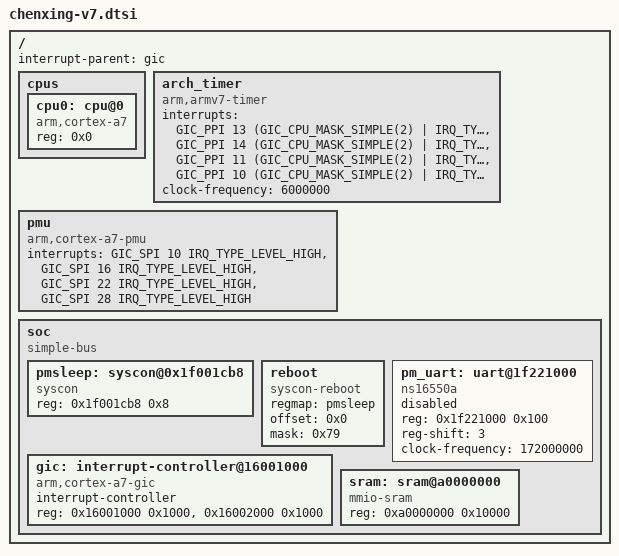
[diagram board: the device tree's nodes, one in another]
// SPDX-License-Identifier: GPL-2.0
/*
 * Copyright (c) 2019 thingy.jp.
 * Author: Daniel Palmer <daniel@thingy.jp>
 */

#include <dt-bindings/interrupt-controller/irq.h>
#include <dt-bindings/interrupt-controller/arm-gic.h>

/ {
	#address-cells = <1>;
	#size-cells = <1>;
	interrupt-parent = <&gic>;

	cpus {
		#address-cells = <1>;
		#size-cells = <0>;

		cpu0: cpu@0 {
			device_type = "cpu";
			compatible = "arm,cortex-a7";
			reg = <0x0>;
		};
	};

	arch_timer {
		compatible = "arm,armv7-timer";
		interrupts = <GIC_PPI 13 (GIC_CPU_MASK_SIMPLE(2)
				| IRQ_TYPE_LEVEL_LOW)>,
			     <GIC_PPI 14 (GIC_CPU_MASK_SIMPLE(2)
				| IRQ_TYPE_LEVEL_LOW)>,
			     <GIC_PPI 11 (GIC_CPU_MASK_SIMPLE(2)
				| IRQ_TYPE_LEVEL_LOW)>,
			     <GIC_PPI 10 (GIC_CPU_MASK_SIMPLE(2)
				| IRQ_TYPE_LEVEL_LOW)>;
		clock-frequency = <6000000>;
	};

	pmu {
		compatible = "arm,cortex-a7-pmu";
		interrupts = <GIC_SPI 10 IRQ_TYPE_LEVEL_HIGH>,
			     <GIC_SPI 16 IRQ_TYPE_LEVEL_HIGH>,
			     <GIC_SPI 22 IRQ_TYPE_LEVEL_HIGH>,
			     <GIC_SPI 28 IRQ_TYPE_LEVEL_HIGH>;
	};

	soc: soc {
		compatible = "simple-bus";
		#address-cells = <1>;
		#size-cells = <1>;
		ranges;

		pmsleep: syscon@0x1f001cb8 {
			/* msc313e notes */
			/* 0x1f001c00 - wake up source */
			/*
			 * 1f001c24 -- bit 11 disables pm uart rx
			 * -- bit 15 is set when going into deep sleep
			 *
			 * mysteryclk1 1f001cf4
			 * 0x1f001cc0 -- ??
			 * 0x1f001cc8  -- set to 9fe8 before deep sleep
			 * 0x1f001ccc  -- set to 9fe8 before deep sleep
			 * 0x1f001cdc  -- set to 0xa5 before deep sleep
			 * 0x1f001c70  -- set to 0x0c before deep sleep
			 * 0x1f001c48  -- set to 0xbabe before deep sleep
			 *
			 * 1f001cec -- return address after resume
			 * 1f001cf0
			 * 1f001cf4 -- clck for timers?
			 */
			/*
			 * 0x1f001cb8 - writing 0x79 triggers a cpu reset
			 * 0x1f001cbc - bit 3 in here controls something to do with the temp sensor
			 */
			compatible = "syscon";
			reg = <0x1f001cb8 0x8>;
		};

		reboot {
			compatible = "syscon-reboot";
			regmap = <&pmsleep>;
			offset = <0x0>;
			mask = <0x79>;
		};

		gic: interrupt-controller@16001000 {
			compatible = "arm,cortex-a7-gic";
			#interrupt-cells = <3>;
			#address-cells = <1>;
			#size-cells = <1>;
			interrupt-controller;
			reg = <0x16001000 0x1000>,
			      <0x16002000 0x1000>;
		};

		pm_uart: uart@1f221000 {
			compatible = "ns16550a";
			reg = <0x1f221000 0x100>;
			reg-shift = <3>;
			clock-frequency = <172000000>;
			status = "disabled";
		};

		sram: sram@a0000000 {
			compatible = "mmio-sram";
			reg = <0xa0000000 0x10000>;
		};
	};
};
